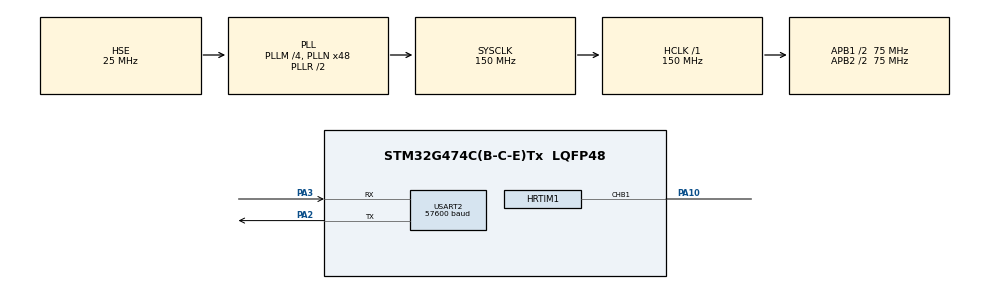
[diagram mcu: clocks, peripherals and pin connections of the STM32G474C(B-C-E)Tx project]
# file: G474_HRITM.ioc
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Mcu.Family=STM32G4
RCC.PLLSourceVirtual=RCC_PLLSOURCE_HSE
HRTIM1.ResetOutput1_Source1-Output_TB1=HRTIM_OUTPUTRESET_TIMCMP1
RCC.CortexFreq_Value=150000000
PA10.Mode=Output_TB1
HRTIM1.CompareValue1-Output_TB1=TIMB_PERIOD * TIMB_DUTY_CYCLE
RCC.EXTERNAL_CLOCK_VALUE=12288000
RCC.APB1CLKDivider=RCC_HCLK_DIV2
USART2.BaudRate=57600
RCC.SYSCLKSource=RCC_SYSCLKSOURCE_PLLCLK
ProjectManager.StackSize=0x400
PA13.Signal=SYS_JTMS-SWDIO
PA3.Mode=Asynchronous
Mcu.UserConstants=HRTIM_INPUT_CLOCK,150000000;TIMB_PWM_FREQ,100000;TIMB_DUTY_CYCLE,0.5
ProjectManager.TargetToolchain=STM32CubeIDE
RCC.HCLKFreq_Value=150000000
RCC.APB2TimFreq_Value=150000000
HRTIM1.NumberSetSource1-Output_TB1=1
RCC.USBFreq_Value=150000000
RCC.LSE_VALUE=32768
RCC.AHBFreq_Value=150000000
PF0-OSC_IN.Mode=HSE-External-Oscillator
RCC.HSE_VALUE=25000000
board=custom
USART2.VirtualMode-Asynchronous=VM_ASYNC
RCC.VCOOutputFreq_Value=300000000
RCC.ADC12Freq_Value=150000000
RCC.ADC345Freq_Value=150000000
RCC.APB2Freq_Value=75000000
PA14.Mode=Serial_Wire
VP_SYS_VS_DBSignals.Mode=DisableDeadBatterySignals
PA13.Mode=Serial_Wire
Mcu.Name=STM32G474C(B-C-E)Tx
PA2.Signal=USART2_TX
RCC.SYSCLKFreq_VALUE=150000000
Mcu.Package=LQFP48
PA10.Signal=HRTIM1_CHB1
PA14.Signal=SYS_JTCK-SWCLK
ProjectManager.HeapSize=0x200
HRTIM1.NumberResetSource1-Output_TB1=1
RCC.HSI_VALUE=16000000
NVIC.PriorityGroup=NVIC_PRIORITYGROUP_4
RCC.APB2CLKDivider=RCC_HCLK_DIV2
RCC.PLLM=RCC_PLLM_DIV4
RCC.PLLN=48
RCC.APB1TimFreq_Value=150000000
PA2.Mode=Asynchronous
HRTIM1.CompareUnit1-Output_TB1=HRTIM_COMPAREUNIT_1
PF0-OSC_IN.Signal=RCC_OSC_IN
HRTIM1.Configuration_TB=Waveform
PF1-OSC_OUT.Mode=HSE-External-Oscillator
RCC.APB1Freq_Value=75000000
HRTIM1.SetOutput1_Source1-Output_TB1=HRTIM_OUTPUTSET_TIMPER
HRTIM1.Periode_TB=TIMB_PERIOD
PF1-OSC_OUT.Signal=RCC_OSC_OUT
RCC.HSI48_VALUE=48000000
PA3.Signal=USART2_RX

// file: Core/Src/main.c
/* USER CODE BEGIN Header */
/**
  ******************************************************************************
  * @file           : main.c
  * @brief          : Main program body
  ******************************************************************************
  * @attention
  *
  * <h2><center>&copy; Copyright (c) 2021 STMicroelectronics.
  * All rights reserved.</center></h2>
  *
  * This software component is licensed by ST under BSD 3-Clause license,
  * the "License"; You may not use this file except in compliance with the
  * License. You may obtain a copy of the License at:
  *                        opensource.org/licenses/BSD-3-Clause
  *
  ******************************************************************************
  */
/* USER CODE END Header */
#include "main.h"

/* USER CODE BEGIN PD */
#define TIMB_PERIOD ((uint16_t)((((uint64_t)HRTIM_INPUT_CLOCK) * 32) / TIMB_PWM_FREQ)) //зададим период ШИМ, в нашем случае 150МГц*32/100кГц=48000=0хВВ80
/* USER CODE END PD */

HRTIM_HandleTypeDef hhrtim1;

UART_HandleTypeDef huart2;

void SystemClock_Config(void);
static void MX_GPIO_Init(void);
static void MX_HRTIM1_Init(void);
static void MX_USART2_UART_Init(void);

int main(void)
{

  /* MCU Configuration--------------------------------------------------------*/

  /* Reset of all peripherals, Initializes the Flash interface and the Systick. */
  HAL_Init();

  /* Configure the system clock */
  SystemClock_Config();

  /* Initialize all configured peripherals */
  MX_GPIO_Init();
  MX_HRTIM1_Init();
  MX_USART2_UART_Init();
  /* USER CODE BEGIN 2 */
  HAL_HRTIM_WaveformOutputStart(&hhrtim1, HRTIM_OUTPUT_TB1); // Enable HRTIM's outputs TB1
  HAL_HRTIM_WaveformCounterStart(&hhrtim1, HRTIM_TIMERID_TIMER_B); //запуск таймера В HRTIM

  /* USER CODE END 2 */

  /* Infinite loop */
  while (1)
  {

  }
}

void SystemClock_Config(void)
{
  RCC_OscInitTypeDef RCC_OscInitStruct = {0};
  RCC_ClkInitTypeDef RCC_ClkInitStruct = {0};
  RCC_PeriphCLKInitTypeDef PeriphClkInit = {0};

  /** Configure the main internal regulator output voltage
  */
  HAL_PWREx_ControlVoltageScaling(PWR_REGULATOR_VOLTAGE_SCALE1);
  /** Initializes the RCC Oscillators according to the specified parameters
  * in the RCC_OscInitTypeDef structure.
  */
  RCC_OscInitStruct.OscillatorType = RCC_OSCILLATORTYPE_HSE;
  RCC_OscInitStruct.HSEState = RCC_HSE_ON;
  RCC_OscInitStruct.PLL.PLLState = RCC_PLL_ON;
  RCC_OscInitStruct.PLL.PLLSource = RCC_PLLSOURCE_HSE;
  RCC_OscInitStruct.PLL.PLLM = RCC_PLLM_DIV4;
  RCC_OscInitStruct.PLL.PLLN = 48;
  RCC_OscInitStruct.PLL.PLLP = RCC_PLLP_DIV2;
  RCC_OscInitStruct.PLL.PLLQ = RCC_PLLQ_DIV2;
  RCC_OscInitStruct.PLL.PLLR = RCC_PLLR_DIV2;
  if (HAL_RCC_OscConfig(&RCC_OscInitStruct) != HAL_OK)
  {
    Error_Handler();
  }
  /** Initializes the CPU, AHB and APB buses clocks
  */
  RCC_ClkInitStruct.ClockType = RCC_CLOCKTYPE_HCLK|RCC_CLOCKTYPE_SYSCLK
                              |RCC_CLOCKTYPE_PCLK1|RCC_CLOCKTYPE_PCLK2;
  RCC_ClkInitStruct.SYSCLKSource = RCC_SYSCLKSOURCE_PLLCLK;
  RCC_ClkInitStruct.AHBCLKDivider = RCC_SYSCLK_DIV1;
  RCC_ClkInitStruct.APB1CLKDivider = RCC_HCLK_DIV2;
  RCC_ClkInitStruct.APB2CLKDivider = RCC_HCLK_DIV2;

  if (HAL_RCC_ClockConfig(&RCC_ClkInitStruct, FLASH_LATENCY_4) != HAL_OK)
  {
    Error_Handler();
  }
  /** Initializes the peripherals clocks
  */
  PeriphClkInit.PeriphClockSelection = RCC_PERIPHCLK_USART2;
  PeriphClkInit.Usart2ClockSelection = RCC_USART2CLKSOURCE_PCLK1;
  if (HAL_RCCEx_PeriphCLKConfig(&PeriphClkInit) != HAL_OK)
  {
    Error_Handler();
  }
}

static void MX_HRTIM1_Init(void)
{

  HRTIM_TimeBaseCfgTypeDef pTimeBaseCfg = {0};
  HRTIM_TimerCtlTypeDef pTimerCtl = {0};
  HRTIM_TimerCfgTypeDef pTimerCfg = {0};
  HRTIM_CompareCfgTypeDef pCompareCfg = {0};
  HRTIM_OutputCfgTypeDef pOutputCfg = {0};

  hhrtim1.Instance = HRTIM1;
  hhrtim1.Init.HRTIMInterruptResquests = HRTIM_IT_NONE;
  hhrtim1.Init.SyncOptions = HRTIM_SYNCOPTION_NONE;
  if (HAL_HRTIM_Init(&hhrtim1) != HAL_OK)
  {
    Error_Handler();
  }
  if (HAL_HRTIM_DLLCalibrationStart(&hhrtim1, HRTIM_CALIBRATIONRATE_3) != HAL_OK)
  {
    Error_Handler();
  }
  if (HAL_HRTIM_PollForDLLCalibration(&hhrtim1, 10) != HAL_OK)
  {
    Error_Handler();
  }
  pTimeBaseCfg.Period = TIMB_PERIOD;
  pTimeBaseCfg.RepetitionCounter = 0x00;
  pTimeBaseCfg.PrescalerRatio = HRTIM_PRESCALERRATIO_MUL32;
  pTimeBaseCfg.Mode = HRTIM_MODE_CONTINUOUS;
  if (HAL_HRTIM_TimeBaseConfig(&hhrtim1, HRTIM_TIMERINDEX_TIMER_B, &pTimeBaseCfg) != HAL_OK)
  {
    Error_Handler();
  }
  pTimerCtl.UpDownMode = HRTIM_TIMERUPDOWNMODE_UP;
  pTimerCtl.GreaterCMP1 = HRTIM_TIMERGTCMP1_EQUAL;
  pTimerCtl.DualChannelDacEnable = HRTIM_TIMER_DCDE_DISABLED;
  if (HAL_HRTIM_WaveformTimerControl(&hhrtim1, HRTIM_TIMERINDEX_TIMER_B, &pTimerCtl) != HAL_OK)
  {
    Error_Handler();
  }
  pTimerCfg.InterruptRequests = HRTIM_TIM_IT_NONE;
  pTimerCfg.DMARequests = HRTIM_TIM_DMA_NONE;
  pTimerCfg.DMASrcAddress = 0x0000;
  pTimerCfg.DMADstAddress = 0x0000;
  pTimerCfg.DMASize = 0x1;
  pTimerCfg.HalfModeEnable = HRTIM_HALFMODE_DISABLED;
  pTimerCfg.InterleavedMode = HRTIM_INTERLEAVED_MODE_DISABLED;
  pTimerCfg.StartOnSync = HRTIM_SYNCSTART_DISABLED;
  pTimerCfg.ResetOnSync = HRTIM_SYNCRESET_DISABLED;
  pTimerCfg.DACSynchro = HRTIM_DACSYNC_NONE;
  pTimerCfg.PreloadEnable = HRTIM_PRELOAD_DISABLED;
  pTimerCfg.UpdateGating = HRTIM_UPDATEGATING_INDEPENDENT;
  pTimerCfg.BurstMode = HRTIM_TIMERBURSTMODE_MAINTAINCLOCK;
  pTimerCfg.RepetitionUpdate = HRTIM_UPDATEONREPETITION_DISABLED;
  pTimerCfg.PushPull = HRTIM_TIMPUSHPULLMODE_DISABLED;
  pTimerCfg.FaultEnable = HRTIM_TIMFAULTENABLE_NONE;
  pTimerCfg.FaultLock = HRTIM_TIMFAULTLOCK_READWRITE;
  pTimerCfg.DeadTimeInsertion = HRTIM_TIMDEADTIMEINSERTION_DISABLED;
  pTimerCfg.DelayedProtectionMode = HRTIM_TIMER_A_B_C_DELAYEDPROTECTION_DISABLED;
  pTimerCfg.UpdateTrigger = HRTIM_TIMUPDATETRIGGER_NONE;
  pTimerCfg.ResetTrigger = HRTIM_TIMRESETTRIGGER_NONE;
  pTimerCfg.ResetUpdate = HRTIM_TIMUPDATEONRESET_DISABLED;
  pTimerCfg.ReSyncUpdate = HRTIM_TIMERESYNC_UPDATE_UNCONDITIONAL;
  if (HAL_HRTIM_WaveformTimerConfig(&hhrtim1, HRTIM_TIMERINDEX_TIMER_B, &pTimerCfg) != HAL_OK)
  {
    Error_Handler();
  }
  pCompareCfg.CompareValue = TIMB_PERIOD * TIMB_DUTY_CYCLE;
  if (HAL_HRTIM_WaveformCompareConfig(&hhrtim1, HRTIM_TIMERINDEX_TIMER_B, HRTIM_COMPAREUNIT_1, &pCompareCfg) != HAL_OK)
  {
    Error_Handler();
  }
  pOutputCfg.Polarity = HRTIM_OUTPUTPOLARITY_HIGH;
  pOutputCfg.SetSource = HRTIM_OUTPUTSET_TIMPER;
  pOutputCfg.ResetSource = HRTIM_OUTPUTRESET_TIMCMP1;
  pOutputCfg.IdleMode = HRTIM_OUTPUTIDLEMODE_NONE;
  pOutputCfg.IdleLevel = HRTIM_OUTPUTIDLELEVEL_INACTIVE;
  pOutputCfg.FaultLevel = HRTIM_OUTPUTFAULTLEVEL_NONE;
  pOutputCfg.ChopperModeEnable = HRTIM_OUTPUTCHOPPERMODE_DISABLED;
  pOutputCfg.BurstModeEntryDelayed = HRTIM_OUTPUTBURSTMODEENTRY_REGULAR;
  if (HAL_HRTIM_WaveformOutputConfig(&hhrtim1, HRTIM_TIMERINDEX_TIMER_B, HRTIM_OUTPUT_TB1, &pOutputCfg) != HAL_OK)
  {
    Error_Handler();
  }
  HAL_HRTIM_MspPostInit(&hhrtim1);

}

static void MX_USART2_UART_Init(void)
{

  huart2.Instance = USART2;
  huart2.Init.BaudRate = 57600;
  huart2.Init.WordLength = UART_WORDLENGTH_8B;
  huart2.Init.StopBits = UART_STOPBITS_1;
  huart2.Init.Parity = UART_PARITY_NONE;
  huart2.Init.Mode = UART_MODE_TX_RX;
  huart2.Init.HwFlowCtl = UART_HWCONTROL_NONE;
  huart2.Init.OverSampling = UART_OVERSAMPLING_16;
  huart2.Init.OneBitSampling = UART_ONE_BIT_SAMPLE_DISABLE;
  huart2.Init.ClockPrescaler = UART_PRESCALER_DIV1;
  huart2.AdvancedInit.AdvFeatureInit = UART_ADVFEATURE_NO_INIT;
  if (HAL_UART_Init(&huart2) != HAL_OK)
  {
    Error_Handler();
  }
  if (HAL_UARTEx_SetTxFifoThreshold(&huart2, UART_TXFIFO_THRESHOLD_1_8) != HAL_OK)
  {
    Error_Handler();
  }
  if (HAL_UARTEx_SetRxFifoThreshold(&huart2, UART_RXFIFO_THRESHOLD_1_8) != HAL_OK)
  {
    Error_Handler();
  }
  if (HAL_UARTEx_DisableFifoMode(&huart2) != HAL_OK)
  {
    Error_Handler();
  }

}

static void MX_GPIO_Init(void)
{

  /* GPIO Ports Clock Enable */
  __HAL_RCC_GPIOF_CLK_ENABLE();
  __HAL_RCC_GPIOA_CLK_ENABLE();

}

void Error_Handler(void)
{
  __disable_irq();
  while (1)
  {
  }
}

/************************ (C) COPYRIGHT STMicroelectronics *****END OF FILE****/
